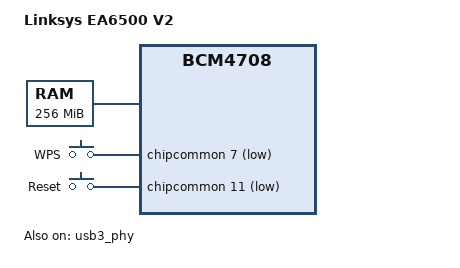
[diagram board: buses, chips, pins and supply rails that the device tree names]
// SPDX-License-Identifier: GPL-2.0-or-later OR MIT
/*
 * Copyright (C) 2017 Rafał Miłecki <rafal@milecki.pl>
 * Copyright (C) 2018 Rene Kjellerup <rk.katana.steel@gmail.com>
 */

/dts-v1/;

#include "bcm4708.dtsi"
#include "bcm5301x-nand-cs0-bch8.dtsi"

/ {
	compatible = "linksys,ea6500-v2", "brcm,bcm4708";
	model = "Linksys EA6500 V2";

	chosen {
		bootargs = "console=ttyS0,115200";
	};

	memory@0 {
		device_type = "memory";
		reg = <0x00000000 0x08000000>,
		      <0x88000000 0x08000000>;
	};

	gpio-keys {
		compatible = "gpio-keys";

		button-wps {
			label = "WPS";
			linux,code = <KEY_WPS_BUTTON>;
			gpios = <&chipcommon 7 GPIO_ACTIVE_LOW>;
		};

		button-restart {
			label = "Reset";
			linux,code = <KEY_RESTART>;
			gpios = <&chipcommon 11 GPIO_ACTIVE_LOW>;
		};
	};
};

&usb3_phy {
	status = "okay";
};
